AUTOSAR XML (schema 00048)
package /HuaweiMDC/FunctionalSoftware/LidarTrackerApplication/Execution
  executable LidarTrackerExecutable
    root sw component prototype LidarTrackerRootSwComponent: application-type=LidarTrackerApplicationSwComponent
package /HuaweiMDC/FunctionalSoftware/LidarTrackerApplication/SwComponent
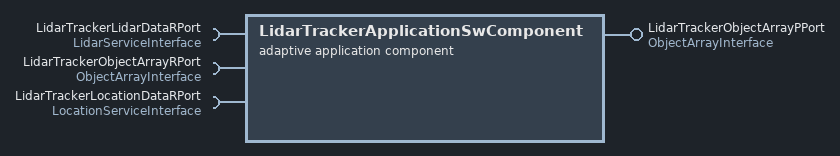
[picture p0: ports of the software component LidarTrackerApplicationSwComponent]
  adaptive application sw component type LidarTrackerApplicationSwComponent
    require port LidarTrackerLidarDataRPort: required-interface=LidarServiceInterface
    provide port LidarTrackerObjectArrayPPort: provided-interface=ObjectArrayInterface
    require port LidarTrackerObjectArrayRPort: required-interface=ObjectArrayInterface
    require port LidarTrackerLocationDataRPort: required-interface=LocationServiceInterface
